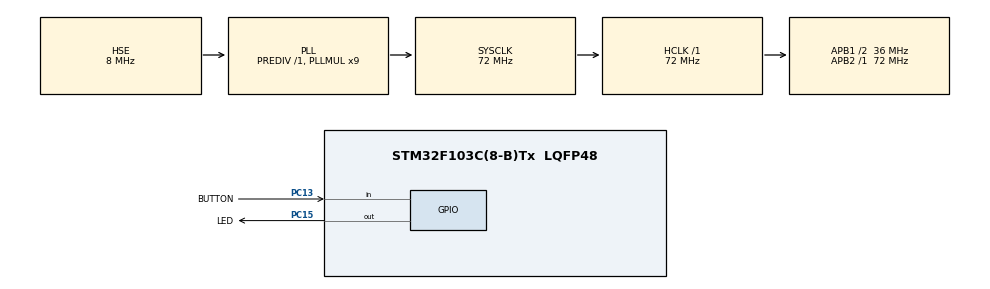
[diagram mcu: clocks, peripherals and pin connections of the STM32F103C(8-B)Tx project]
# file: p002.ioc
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Mcu.Family=STM32F1
Mcu.Name=STM32F103C(8-B)Tx
Mcu.Package=LQFP48
NVIC.PriorityGroup=NVIC_PRIORITYGROUP_4
PA13.Mode=Serial_Wire
PA13.Signal=SYS_JTMS-SWDIO
PA14.Mode=Serial_Wire
PA14.Signal=SYS_JTCK-SWCLK
PC13-TAMPER-RTC.GPIO_Label=BUTTON
PC13-TAMPER-RTC.GPIO_PuPd=GPIO_PULLUP
PC13-TAMPER-RTC.Signal=GPIO_Input
PC15-OSC32_OUT.GPIO_Label=LED
PC15-OSC32_OUT.GPIO_PuPd=GPIO_PULLUP
PC15-OSC32_OUT.PinState=GPIO_PIN_SET
PC15-OSC32_OUT.Signal=GPIO_Output
PD0-OSC_IN.Mode=HSE-External-Oscillator
PD0-OSC_IN.Signal=RCC_OSC_IN
PD1-OSC_OUT.Mode=HSE-External-Oscillator
PD1-OSC_OUT.Signal=RCC_OSC_OUT
ProjectManager.HeapSize=0x200
ProjectManager.StackSize=0x400
ProjectManager.TargetToolchain=EWARM V8
RCC.AHBFreq_Value=72000000
RCC.APB1CLKDivider=RCC_HCLK_DIV2
RCC.APB1Freq_Value=36000000
RCC.APB1TimFreq_Value=72000000
RCC.APB2Freq_Value=72000000
RCC.APB2TimFreq_Value=72000000
RCC.HCLKFreq_Value=72000000
RCC.PLLMUL=RCC_PLL_MUL9
RCC.PLLSourceVirtual=RCC_PLLSOURCE_HSE
RCC.SYSCLKFreq_VALUE=72000000
RCC.SYSCLKSource=RCC_SYSCLKSOURCE_PLLCLK
RCC.USBFreq_Value=72000000
board=custom

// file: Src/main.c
/* USER CODE BEGIN Header */
/**
  ******************************************************************************
  * @file           : main.c
  * @brief          : Main program body
  ******************************************************************************
  * @attention
  *
  * <h2><center>&copy; Copyright (c) 2019 STMicroelectronics.
  * All rights reserved.</center></h2>
  *
  * This software component is licensed by ST under BSD 3-Clause license,
  * the "License"; You may not use this file except in compliance with the
  * License. You may obtain a copy of the License at:
  *                        opensource.org/licenses/BSD-3-Clause
  *
  ******************************************************************************
  */
/* USER CODE END Header */

#include "main.h"
#include "gpio.h"

void SystemClock_Config(void);

int main(void)
{

  /* MCU Configuration--------------------------------------------------------*/

  /* Reset of all peripherals, Initializes the Flash interface and the Systick. */
  HAL_Init();

  /* Configure the system clock */
  SystemClock_Config();

  /* Initialize all configured peripherals */
  MX_GPIO_Init();

  /* Infinite loop */
  while (1)
  {

    /* USER CODE BEGIN 3 */

    //  按键灯
    if(HAL_GPIO_ReadPin(BUTTON_GPIO_Port, BUTTON_Pin) == RESET) //按下按键
    {
      HAL_Delay(20);    //按键延时消抖
      if(HAL_GPIO_ReadPin(BUTTON_GPIO_Port, BUTTON_Pin) == RESET)       //按键仍在按下状态
      {
        HAL_GPIO_TogglePin(LED_GPIO_Port, LED_Pin);     //翻转IO
        while(HAL_GPIO_ReadPin(BUTTON_GPIO_Port, BUTTON_Pin) == RESET)  //等待松开按键
        {

        }
      }
    }
  }
  /* USER CODE END 3 */
}

void SystemClock_Config(void)
{
  RCC_OscInitTypeDef RCC_OscInitStruct = {0};
  RCC_ClkInitTypeDef RCC_ClkInitStruct = {0};

  /** Initializes the CPU, AHB and APB busses clocks
  */
  RCC_OscInitStruct.OscillatorType = RCC_OSCILLATORTYPE_HSE;
  RCC_OscInitStruct.HSEState = RCC_HSE_ON;
  RCC_OscInitStruct.HSEPredivValue = RCC_HSE_PREDIV_DIV1;
  RCC_OscInitStruct.HSIState = RCC_HSI_ON;
  RCC_OscInitStruct.PLL.PLLState = RCC_PLL_ON;
  RCC_OscInitStruct.PLL.PLLSource = RCC_PLLSOURCE_HSE;
  RCC_OscInitStruct.PLL.PLLMUL = RCC_PLL_MUL9;
  if (HAL_RCC_OscConfig(&RCC_OscInitStruct) != HAL_OK)
  {
    Error_Handler();
  }
  /** Initializes the CPU, AHB and APB busses clocks
  */
  RCC_ClkInitStruct.ClockType = RCC_CLOCKTYPE_HCLK|RCC_CLOCKTYPE_SYSCLK
                              |RCC_CLOCKTYPE_PCLK1|RCC_CLOCKTYPE_PCLK2;
  RCC_ClkInitStruct.SYSCLKSource = RCC_SYSCLKSOURCE_PLLCLK;
  RCC_ClkInitStruct.AHBCLKDivider = RCC_SYSCLK_DIV1;
  RCC_ClkInitStruct.APB1CLKDivider = RCC_HCLK_DIV2;
  RCC_ClkInitStruct.APB2CLKDivider = RCC_HCLK_DIV1;

  if (HAL_RCC_ClockConfig(&RCC_ClkInitStruct, FLASH_LATENCY_2) != HAL_OK)
  {
    Error_Handler();
  }
}

void Error_Handler(void)
{
}

/************************ (C) COPYRIGHT STMicroelectronics *****END OF FILE****/
